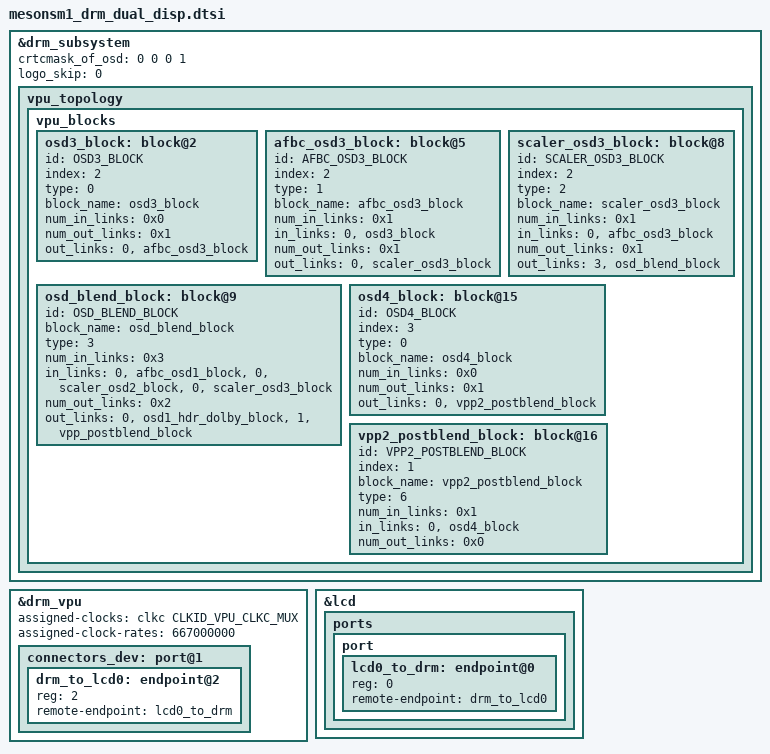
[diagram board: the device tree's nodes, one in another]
// SPDX-License-Identifier: (GPL-2.0+ OR MIT)
/*
 * Copyright (c) 2023 Amlogic, Inc. All rights reserved.
 */

#include "mesonsm1_drm.dtsi"

&drm_subsystem {
		crtcmask_of_osd = <0 0 0 1>;
		logo_skip = <0>;
		vpu_topology: vpu_topology {
			vpu_blocks {
				osd3_block: block@2 {
					id = /bits/ 8  <OSD3_BLOCK>;
					index = /bits/ 8  <2>;
					type = /bits/ 8  <0>;
					block_name = "osd3_block";
					num_in_links = /bits/ 8  <0x0>;
					num_out_links = /bits/ 8  <0x1>;
					out_links = <0 &afbc_osd3_block>;
				};
				afbc_osd3_block: block@5 {
					id = /bits/ 8  <AFBC_OSD3_BLOCK>;
					index = /bits/ 8  <2>;
					type = /bits/ 8  <1>;
					block_name = "afbc_osd3_block";
					num_in_links = /bits/ 8  <0x1>;
					in_links = <0 &osd3_block>;
					num_out_links = /bits/ 8  <0x1>;
					out_links = <0 &scaler_osd3_block>;
				};
				scaler_osd3_block: block@8 {
					id = /bits/ 8  <SCALER_OSD3_BLOCK>;
					index = /bits/ 8  <2>;
					type = /bits/ 8  <2>;
					block_name = "scaler_osd3_block";
					num_in_links = /bits/ 8  <0x1>;
					in_links = <0 &afbc_osd3_block>;
					num_out_links = /bits/ 8  <0x1>;
					out_links = <3 &osd_blend_block>;
				};
				osd_blend_block: block@9 {
					id = /bits/ 8  <OSD_BLEND_BLOCK>;
					block_name = "osd_blend_block";
					type = /bits/ 8  <3>;
					num_in_links = /bits/ 8  <0x3>;
					in_links = <0 &afbc_osd1_block>,
						<0 &scaler_osd2_block>,
						<0 &scaler_osd3_block>;
					num_out_links = /bits/ 8  <0x2>;
					out_links = <0 &osd1_hdr_dolby_block>,
						<1 &vpp_postblend_block>;
				};
				osd4_block: block@15 {
					id = /bits/ 8  <OSD4_BLOCK>;
					index = /bits/ 8  <3>;
					type = /bits/ 8  <0>;
					block_name = "osd4_block";
					num_in_links = /bits/ 8  <0x0>;
					num_out_links = /bits/ 8  <0x1>;
					out_links = <0 &vpp2_postblend_block>;
				};
				vpp2_postblend_block: block@16 {
					id = /bits/ 8  <VPP2_POSTBLEND_BLOCK>;
					index = /bits/ 8  <1>;
					block_name = "vpp2_postblend_block";
					type = /bits/ 8  <6>;
					num_in_links = /bits/ 8  <0x1>;
					in_links = <0 &osd4_block>;
					num_out_links = <0x0>;
				};
			};
		};
};

&drm_vpu {
	assigned-clocks = <&clkc CLKID_VPU_CLKC_MUX>;
	assigned-clock-rates = <667000000>;
	connectors_dev: port@1 {
		drm_to_lcd0: endpoint@2 {
			reg = <2>;
			remote-endpoint = <&lcd0_to_drm>;
		};
	};
};

&lcd {
	ports {
		port {
			#address-cells = <1>;
			#size-cells = <0>;
			lcd0_to_drm: endpoint@0 {
				reg = <0>;
				remote-endpoint = <&drm_to_lcd0>;
			};
		};
	};
};
